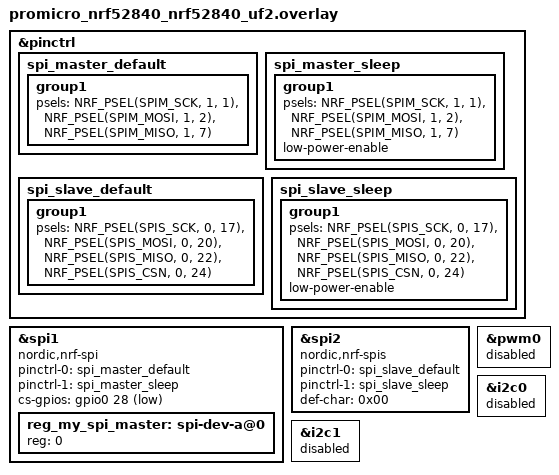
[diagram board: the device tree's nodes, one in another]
&pinctrl {
	// copied from 
	spi_master_default: spi_master_default {
		group1 {
			psels = <NRF_PSEL(SPIM_SCK,  1, 1)>,
					<NRF_PSEL(SPIM_MOSI, 1, 2)>,
					<NRF_PSEL(SPIM_MISO, 1, 7)>;
		};
	};

	spi_master_sleep: spi_master_sleep {
		group1 {
			psels = <NRF_PSEL(SPIM_SCK,  1, 1)>,
					<NRF_PSEL(SPIM_MOSI, 1, 2)>,
					<NRF_PSEL(SPIM_MISO, 1, 7)>;
			low-power-enable;
		};
	};

	spi_slave_default: spi_slave_default {
		group1 {
			psels = <NRF_PSEL(SPIS_SCK,  0, 17)>,
					<NRF_PSEL(SPIS_MOSI, 0, 20)>,
					<NRF_PSEL(SPIS_MISO, 0, 22)>,
					<NRF_PSEL(SPIS_CSN,  0, 24)>; // idk some random
		};
	};

	spi_slave_sleep: spi_slave_sleep {
		group1 {
			psels = <NRF_PSEL(SPIS_SCK,  0, 17)>,
					<NRF_PSEL(SPIS_MOSI, 0, 20)>,
					<NRF_PSEL(SPIS_MISO, 0, 22)>,
					<NRF_PSEL(SPIS_CSN,  0, 24)>; // idk some random
			low-power-enable;
		};
	};

};

// my_spi_master: &spi1
my_spi_master: &spi1 { // swapped
	compatible = "nordic,nrf-spi";
	status = "okay";
	pinctrl-0 = <&spi_master_default>;
	pinctrl-1 = <&spi_master_sleep>;
	pinctrl-names = "default", "sleep";
	cs-gpios = <&gpio0 28 GPIO_ACTIVE_LOW>;
	reg_my_spi_master: spi-dev-a@0 {
		reg = <0>;
	};
};

// idk
my_spi_slave: &spi2 {
	compatible = "nordic,nrf-spis";
	status = "okay";
	pinctrl-0 = <&spi_slave_default>;
	pinctrl-1 = <&spi_slave_sleep>;
	pinctrl-names = "default", "sleep";
	def-char = <0x00>;
};


// free P0.17
&pwm0 {
	status="disabled";
};

// idk just in case
&i2c0 {
	status="disabled";
};
&i2c1 {
	status="disabled";
};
